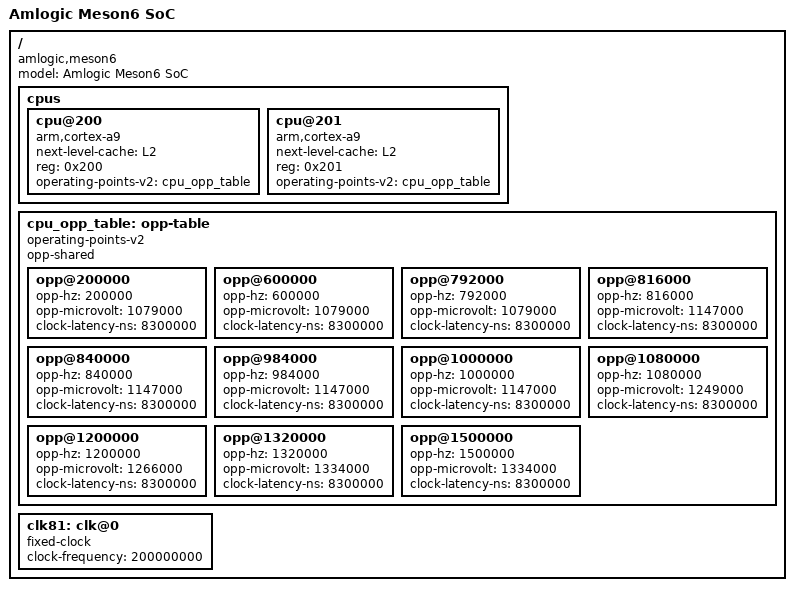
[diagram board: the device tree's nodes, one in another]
/*
 * Copyright 2014 Carlo Caione <carlo@caione.org>
 *
 * This file is dual-licensed: you can use it either under the terms
 * of the GPL or the X11 license, at your option. Note that this dual
 * licensing only applies to this file, and not this project as a
 * whole.
 *
 *  a) This library is free software; you can redistribute it and/or
 *     modify it under the terms of the GNU General Public License as
 *     published by the Free Software Foundation; either version 2 of the
 *     License, or (at your option) any later version.
 *
 *     This library is distributed in the hope that it will be useful,
 *     but WITHOUT ANY WARRANTY; without even the implied warranty of
 *     MERCHANTABILITY or FITNESS FOR A PARTICULAR PURPOSE.  See the
 *     GNU General Public License for more details.
 *
 *     You should have received a copy of the GNU General Public
 *     License along with this library; if not, write to the Free
 *     Software Foundation, Inc., 51 Franklin St, Fifth Floor, Boston,
 *     MA 02110-1301 USA
 *
 * Or, alternatively,
 *
 *  b) Permission is hereby granted, free of charge, to any person
 *     obtaining a copy of this software and associated documentation
 *     files (the "Software"), to deal in the Software without
 *     restriction, including without limitation the rights to use,
 *     copy, modify, merge, publish, distribute, sublicense, and/or
 *     sell copies of the Software, and to permit persons to whom the
 *     Software is furnished to do so, subject to the following
 *     conditions:
 *
 *     The above copyright notice and this permission notice shall be
 *     included in all copies or substantial portions of the Software.
 *
 *     THE SOFTWARE IS PROVIDED "AS IS", WITHOUT WARRANTY OF ANY KIND,
 *     EXPRESS OR IMPLIED, INCLUDING BUT NOT LIMITED TO THE WARRANTIES
 *     OF MERCHANTABILITY, FITNESS FOR A PARTICULAR PURPOSE AND
 *     NONINFRINGEMENT. IN NO EVENT SHALL THE AUTHORS OR COPYRIGHT
 *     HOLDERS BE LIABLE FOR ANY CLAIM, DAMAGES OR OTHER LIABILITY,
 *     WHETHER IN AN ACTION OF CONTRACT, TORT OR OTHERWISE, ARISING
 *     FROM, OUT OF OR IN CONNECTION WITH THE SOFTWARE OR THE USE OR
 *     OTHER DEALINGS IN THE SOFTWARE.
 */

#include "meson.dtsi"

/ {
	model = "Amlogic Meson6 SoC";
	compatible = "amlogic,meson6";

	cpus {
		#address-cells = <1>;
		#size-cells = <0>;

		cpu@200 {
			device_type = "cpu";
			compatible = "arm,cortex-a9";
			next-level-cache = <&L2>;
			reg = <0x200>;
			operating-points-v2 = <&cpu_opp_table>;
		};

		cpu@201 {
			device_type = "cpu";
			compatible = "arm,cortex-a9";
			next-level-cache = <&L2>;
			reg = <0x201>;
			operating-points-v2 = <&cpu_opp_table>;
		};
	};

	cpu_opp_table: opp-table {
		compatible = "operating-points-v2";
		opp-shared;

		opp@200000 {
			opp-hz = /bits/ 64 <200000>;
			opp-microvolt = <1079000>;
			clock-latency-ns = <8300000>;
		};
		opp@600000 {
			opp-hz = /bits/ 64 <600000>;
			opp-microvolt = <1079000>;
			clock-latency-ns = <8300000>;
		};
		opp@792000 {
			opp-hz = /bits/ 64 <792000>;
			opp-microvolt = <1079000>;
			clock-latency-ns = <8300000>;
		};
		opp@816000 {
			opp-hz = /bits/ 64 <816000>;
			opp-microvolt = <1147000>;
			clock-latency-ns = <8300000>;
		};
		opp@840000 {
			opp-hz = /bits/ 64 <840000>;
			opp-microvolt = <1147000>;
			clock-latency-ns = <8300000>;
		};
		opp@984000 {
			opp-hz = /bits/ 64 <984000>;
			opp-microvolt = <1147000>;
			clock-latency-ns = <8300000>;
		};
		opp@1000000 {
			opp-hz = /bits/ 64 <1000000>;
			opp-microvolt = <1147000>;
			clock-latency-ns = <8300000>;
		};
		opp@1080000 {
			opp-hz = /bits/ 64 <1080000>;
			opp-microvolt = <1249000>;
			clock-latency-ns = <8300000>;
		};
		opp@1200000 {
			opp-hz = /bits/ 64 <1200000>;
			opp-microvolt = <1266000>;
			clock-latency-ns = <8300000>;
		};
		opp@1320000 {
			opp-hz = /bits/ 64 <1320000>;
			opp-microvolt = <1334000>;
			clock-latency-ns = <8300000>;
		};
		opp@1500000 {
			opp-hz = /bits/ 64 <1500000>;
			opp-microvolt = <1334000>;
			clock-latency-ns = <8300000>;
		};
	};

	clk81: clk@0 {
		#clock-cells = <0>;
		compatible = "fixed-clock";
		clock-frequency = <200000000>;
	};
}; /* end of / */
